VERSION "0.1"

NS_ :

BS_: 1000000

BU_: PC X

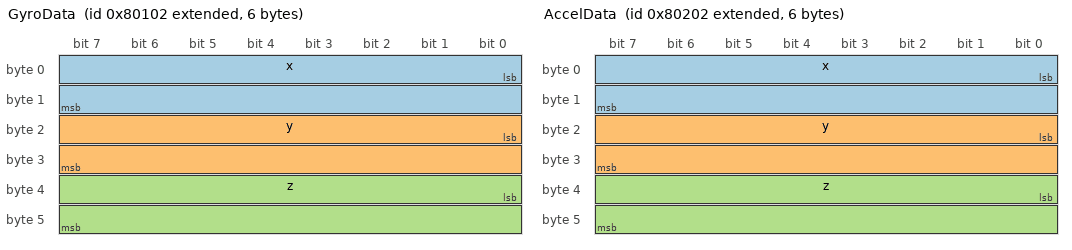
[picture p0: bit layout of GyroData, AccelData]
BO_ 2148008194 GyroData: 6 Vector__XXX
    SG_ x : 0|16@1- (1,0) [0|1000] "mdps" Vector__XXX
    SG_ y : 16|16@1- (1,0) [0|1000] "mdps" Vector__XXX
    SG_ z : 32|16@1- (1,0) [0|1000] "mdps" Vector__XXX

BO_ 2148008450 AccelData: 6 Vector__XXX
    SG_ x : 0|16@1- (1,0) [0|1000] "g" Vector__XXX
    SG_ y : 16|16@1- (1,0) [0|1000] "g" Vector__XXX
    SG_ z : 32|16@1- (1,0) [0|1000] "g" Vector__XXX

BO_ 2148008706 TiltAngles: 8 Vector__XXX
    SG_ pitch : 0|32@1+ (1,0) [0|0] "degrees" Vector__XXX
    SG_ roll : 32|32@1+ (1,0) [0|0] "degrees" Vector__XXX

BO_ 2148077570 Ack: 4 Vector__XXX
    SG_ ident : 0|32@1+ (1,0) [0|4294967295] ""  Vector__XXX

BA_DEF_DEF_ "BusType" "CAN";

SIG_VALTYPE_ 2148008706 pitch : 1;
SIG_VALTYPE_ 2148008706 roll : 1;
